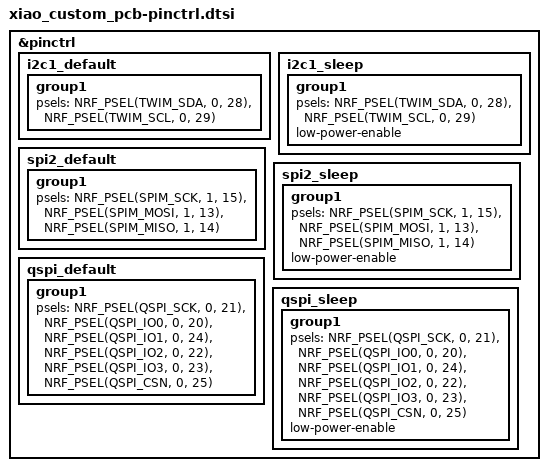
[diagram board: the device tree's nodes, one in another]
/*
 * Copyright (c) 2022 Marcin Niestroj
 * SPDX-License-Identifier: Apache-2.0
 */

&pinctrl {
	i2c1_default: i2c1_default {
		group1 {
			psels = <NRF_PSEL(TWIM_SDA, 0, 28)>,
				<NRF_PSEL(TWIM_SCL, 0, 29)>;
		};
	};

	i2c1_sleep: i2c1_sleep {
		group1 {
			psels = <NRF_PSEL(TWIM_SDA, 0, 28)>,
				<NRF_PSEL(TWIM_SCL, 0, 29)>;
			low-power-enable;
		};
	};

	spi2_default: spi2_default {
		group1 {
			psels = <NRF_PSEL(SPIM_SCK, 1, 15)>,
				<NRF_PSEL(SPIM_MOSI, 1, 13)>,
				<NRF_PSEL(SPIM_MISO, 1, 14)>;
		};
	};

	spi2_sleep: spi2_sleep {
		group1 {
			psels = <NRF_PSEL(SPIM_SCK, 1, 15)>,
				<NRF_PSEL(SPIM_MOSI, 1, 13)>,
				<NRF_PSEL(SPIM_MISO, 1, 14)>;
			low-power-enable;
		};
	};

	qspi_default: qspi_default {
		group1 {
			psels = <NRF_PSEL(QSPI_SCK, 0, 21)>,
				<NRF_PSEL(QSPI_IO0, 0, 20)>,
				<NRF_PSEL(QSPI_IO1, 0, 24)>,
				<NRF_PSEL(QSPI_IO2, 0, 22)>,
				<NRF_PSEL(QSPI_IO3, 0, 23)>,
				<NRF_PSEL(QSPI_CSN, 0, 25)>;
		};
	};

	qspi_sleep: qspi_sleep {
		group1 {
			psels = <NRF_PSEL(QSPI_SCK, 0, 21)>,
				<NRF_PSEL(QSPI_IO0, 0, 20)>,
				<NRF_PSEL(QSPI_IO1, 0, 24)>,
				<NRF_PSEL(QSPI_IO2, 0, 22)>,
				<NRF_PSEL(QSPI_IO3, 0, 23)>,
				<NRF_PSEL(QSPI_CSN, 0, 25)>;
			low-power-enable;
		};
	};
};
